# SWM260 register map
File version: 1.0
CPU: CM0 r1p0, little endian, 2 interrupt priority bits
Registers are 32-bit, read-write, no defined reset value unless marked. A register's access mark holds for its fields unless they carry their own. Offsets are from the block's base; [hi:lo] are bit positions; lines under a group give offsets from that group; {n}, {i} and the like mark numbered series; 'fields as' and 'values as' point back to an identical list.

## TIMR0 — Registers group
Base 0x40046800
Same registers: TIMR1 0x40046840, TIMR2 0x40046880, TIMR3 0x400468C0, BTIMR0 0x40048800, BTIMR1 0x40048840, BTIMR2 0x40048880, BTIMR3 0x400488C0
0x00 LOAD
  [24] LOAD
0x04 VALUE ro
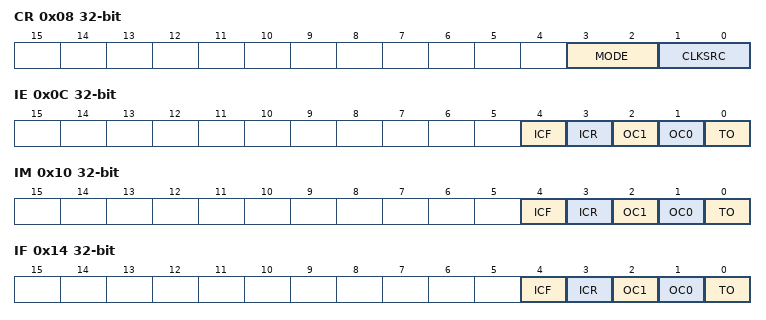
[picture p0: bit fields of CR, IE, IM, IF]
0x08 CR
  [3:2] MODE, [1:0] CLKSRC
0x08 PREDIV (alternate view of CR)
0x0C IE
  [4] ICF, [3] ICR, [2] OC1, [1] OC0, [0] TO
0x10 IM
  [4] ICF, [3] ICR, [2] OC1, [1] OC0, [0] TO
0x14 IF
  [4] ICF, [3] ICR, [2] OC1, [1] OC0, [0] TO
0x18 HALT
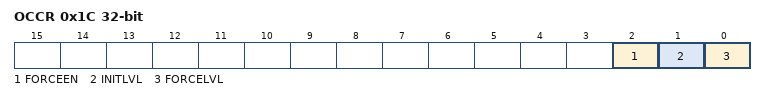
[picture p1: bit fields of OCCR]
0x1C OCCR
  [2] FORCEEN, [1] INITLVL, [0] FORCELVL
0x20 OCMAT0
0x24 OCMAT1
0x28 ICLOW
0x2C ICHIGH

## TIMRG — Registers group
Base 0x40046C00
Same registers: BTIMRG 0x40048C00
0x00 HALLIE
0x04 HALLIM
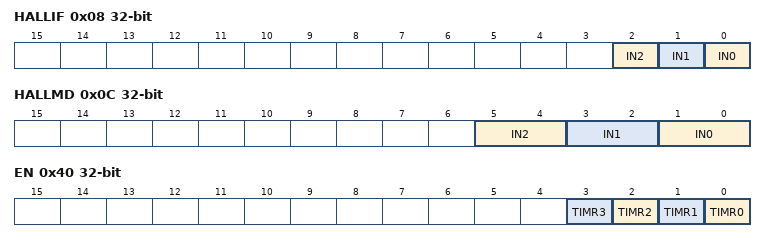
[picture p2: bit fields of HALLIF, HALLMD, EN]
0x08 HALLIF
  [2] IN2, [1] IN1, [0] IN0
0x0C HALLMD
  [5:4] IN2, [3:2] IN1, [1:0] IN0
{0x10+4i} HALLV{i} (i=0..2)
0x40 EN
  [n] TIMR{n} (n=0..3)

## UART0 — Registers group
Base 0x40042000
Same registers: UART1 0x40042800, UART2 0x40043000, UART3 0x40043800, UART4 0x400A3000
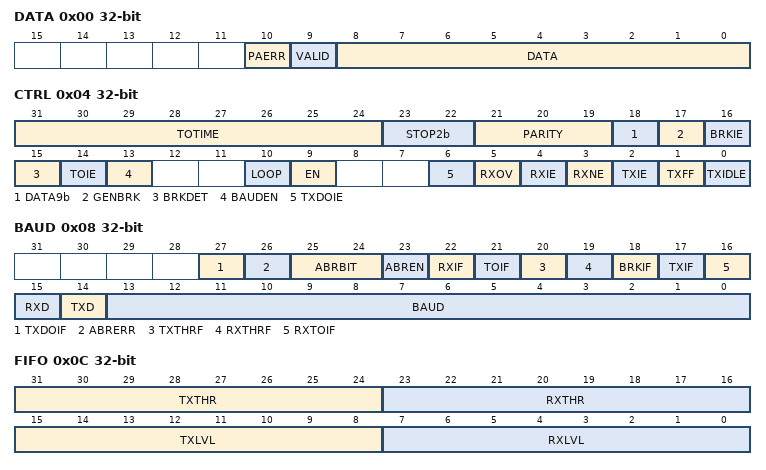
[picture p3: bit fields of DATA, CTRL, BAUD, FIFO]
0x00 DATA
  [10] PAERR, [9] VALID, [8:0] DATA
0x04 CTRL
  [31:24] TOTIME, [23:22] STOP2b, [21:19] PARITY, [18] DATA9b, [17] GENBRK, [16] BRKIE, [15] BRKDET, [14] TOIE, [13] BAUDEN, [10] LOOP, [9] EN, [6] TXDOIE, [5] RXOV, [4] RXIE, [3] RXNE, [2] TXIE, [1] TXFF, [0] TXIDLE
0x08 BAUD
  [27] TXDOIF, [26] ABRERR, [25:24] ABRBIT, [23] ABREN, [22] RXIF, [21] TOIF, [20] TXTHRF, [19] RXTHRF, [18] BRKIF, [17] TXIF, [16] RXTOIF, [15] RXD, [14] TXD, [13:0] BAUD
0x0C FIFO
  [31:24] TXTHR, [23:16] RXTHR, [15:8] TXLVL, [7:0] RXLVL
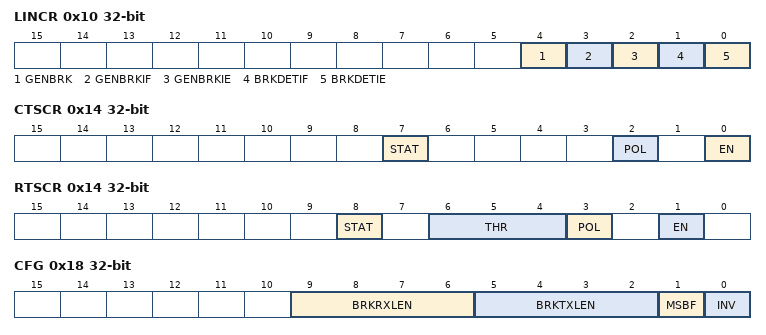
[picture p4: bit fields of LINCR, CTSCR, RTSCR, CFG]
0x10 LINCR
  [4] GENBRK, [3] GENBRKIF, [2] GENBRKIE, [1] BRKDETIF, [0] BRKDETIE
0x14 CTSCR
  [7] STAT, [2] POL, [0] EN
0x14 RTSCR (alternate view of CTSCR)
  [8] STAT, [6:4] THR, [3] POL, [1] EN
0x18 CFG
  [9:6] BRKRXLEN, [5:2] BRKTXLEN, [1] MSBF, [0] INV

## SPI0 — Registers group
Base 0x40044000
Same registers: SPI1 0x40044800
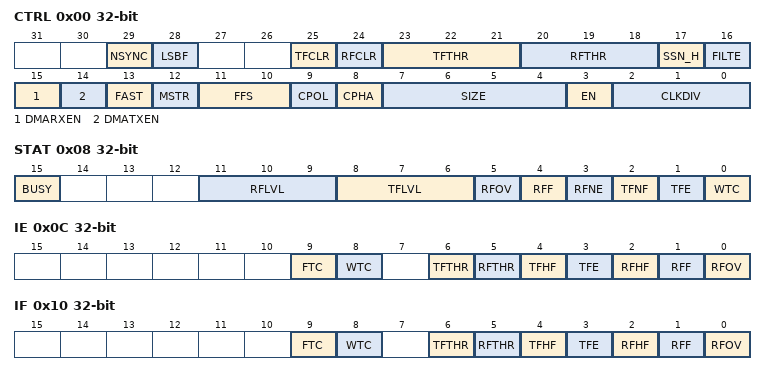
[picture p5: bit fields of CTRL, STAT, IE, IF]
0x00 CTRL
  [29] NSYNC, [28] LSBF, [25] TFCLR, [24] RFCLR, [23:21] TFTHR, [20:18] RFTHR, [17] SSN_H, [16] FILTE, [15] DMARXEN, [14] DMATXEN, [13] FAST, [12] MSTR, [11:10] FFS, [9] CPOL, [8] CPHA, [7:4] SIZE, [3] EN, [2:0] CLKDIV
0x04 DATA
0x08 STAT
  [15] BUSY, [11:9] RFLVL, [8:6] TFLVL, [5] RFOV, [4] RFF, [3] RFNE, [2] TFNF, [1] TFE, [0] WTC
0x0C IE
  [9] FTC, [8] WTC, [6] TFTHR, [5] RFTHR, [4] TFHF, [3] TFE, [2] RFHF, [1] RFF, [0] RFOV
0x10 IF
  fields as IE

## I2C4 — Registers group
Base 0x40045000
0x00 CLKDIV
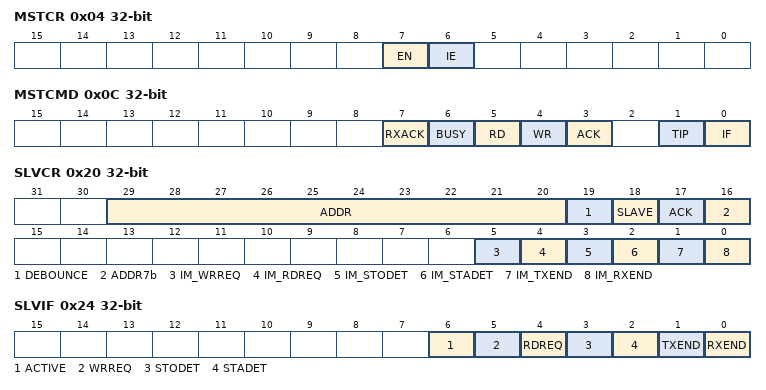
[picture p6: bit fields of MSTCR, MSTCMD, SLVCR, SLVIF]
0x04 MSTCR
  [7] EN, [6] IE
0x08 MSTDAT
0x0C MSTCMD
  [7] RXACK, [6] BUSY, [5] RD, [4] WR, [3] ACK, [1] TIP, [0] IF
0x20 SLVCR
  [29:20] ADDR, [19] DEBOUNCE, [18] SLAVE, [17] ACK, [16] ADDR7b, [5] IM_WRREQ, [4] IM_RDREQ, [3] IM_STODET, [2] IM_STADET, [1] IM_TXEND, [0] IM_RXEND
0x24 SLVIF
  [6] ACTIVE, [5] WRREQ, [4] RDREQ, [3] STODET, [2] STADET, [1] TXEND, [0] RXEND
0x28 SLVTX
0x2C SLVRX
0x30 SLVAM

## ADC0 — Registers group
Base 0x40049000
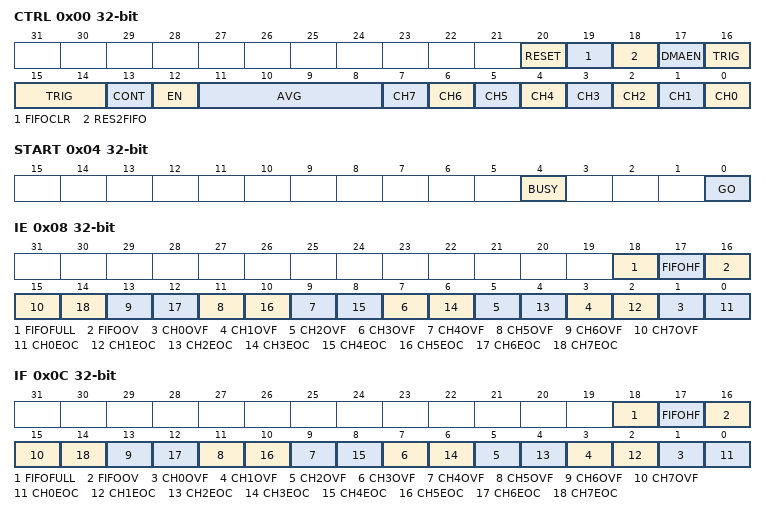
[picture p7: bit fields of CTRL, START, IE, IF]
0x00 CTRL
  [20] RESET, [19] FIFOCLR, [18] RES2FIFO, [17] DMAEN, [16:14] TRIG, [13] CONT, [12] EN, [11:8] AVG, [n] CH{n} (n=0..7)
0x04 START
  [4] BUSY, [0] GO
0x08 IE
  [18] FIFOFULL, [17] FIFOHF, [16] FIFOOV, [2n+1] CH{n}OVF (n=0..7), [2n] CH{n}EOC (n=0..7)
0x0C IF
  fields as IE
{0x10+0x10*i} CH{i} group (i=0..7) — register cluster
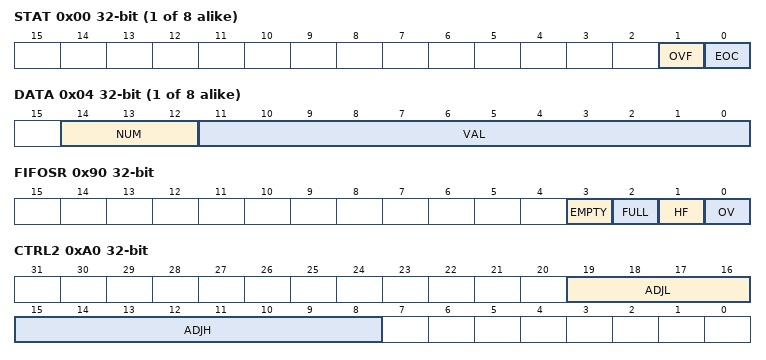
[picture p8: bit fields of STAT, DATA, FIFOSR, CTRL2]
  0x00 STAT
    [1] OVF, [0] EOC
  0x04 DATA
    [14:12] NUM, [11:0] VAL
0x90 FIFOSR
  [3] EMPTY, [2] FULL, [1] HF, [0] OV
0x94 FIFODR
0xA0 CTRL2
  [19:16] ADJL, [15:8] ADJH
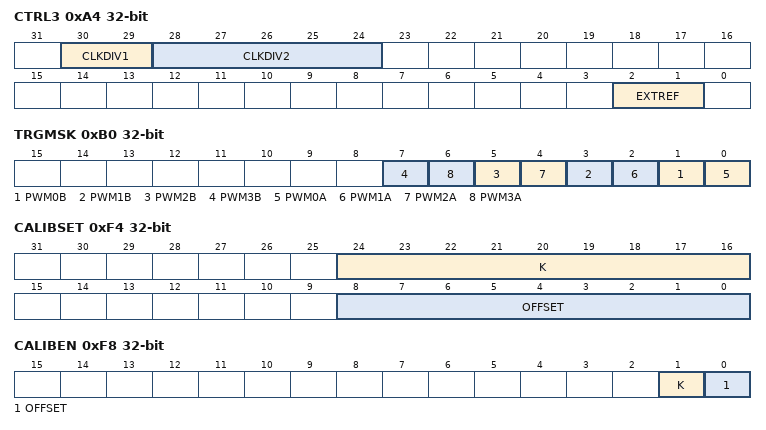
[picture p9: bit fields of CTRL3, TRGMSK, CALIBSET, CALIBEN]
0xA4 CTRL3
  [30:29] CLKDIV1, [28:24] CLKDIV2, [2:1] EXTREF
0xB0 TRGMSK
  [2n+1] PWM{n}B (n=0..3), [2n] PWM{n}A (n=0..3)
0xF4 CALIBSET
  [24:16] K, [8:0] OFFSET
0xF8 CALIBEN
  [1] K, [0] OFFSET

## PWM0 — Registers group
Base 0x40046000
Same registers: PWM1 0x40046040, PWM2 0x40046080, PWM3 0x400460C0
0x00 MODE
0x04 PERA
0x08 HIGHA
0x0C DZA
0x10 PERB
0x14 HIGHB
0x18 DZB
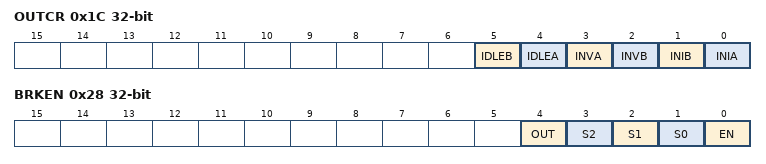
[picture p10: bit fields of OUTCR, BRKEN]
0x1C OUTCR
  [5] IDLEB, [4] IDLEA, [3] INVA, [2] INVB, [1] INIB, [0] INIA
0x20 ADTRGA0
0x24 ADTRGA1
0x28 BRKEN
  [4] OUT, [3] S2, [2] S1, [1] S0, [0] EN
0x2C VALUEA
0x30 VALUEB
0x34 ADTRGB0
0x38 ADTRGB1

## PWMG — Registers group
Base 0x40046200
0x00 CLKDIV
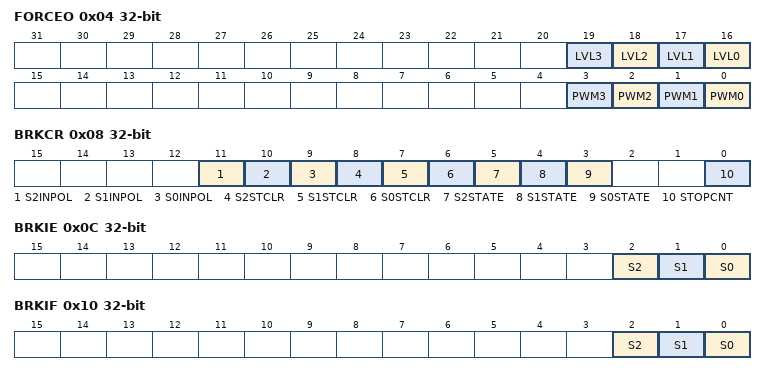
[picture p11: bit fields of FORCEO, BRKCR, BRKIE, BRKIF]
0x04 FORCEO
  [n+16] LVL{n} (n=0..3), [n] PWM{n} (n=0..3)
0x08 BRKCR
  [11] S2INPOL, [10] S1INPOL, [9] S0INPOL, [8] S2STCLR, [7] S1STCLR, [6] S0STCLR, [5] S2STATE, [4] S1STATE, [3] S0STATE, [0] STOPCNT
0x0C BRKIE
  [2] S2, [1] S1, [0] S0
0x10 BRKIF ro
  [2] S2, [1] S1, [0] S0
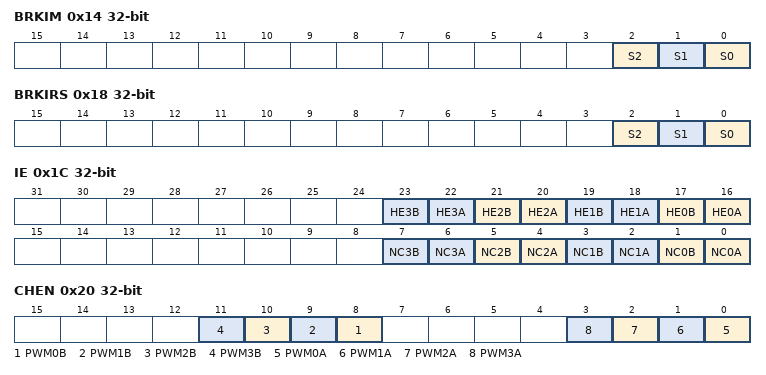
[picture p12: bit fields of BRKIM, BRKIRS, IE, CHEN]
0x14 BRKIM
  [2] S2, [1] S1, [0] S0
0x18 BRKIRS
  [2] S2, [1] S1, [0] S0
0x1C IE
  [2n+17] HE{n}B (n=0..3), [2n+16] HE{n}A (n=0..3), [2n+1] NC{n}B (n=0..3), [2n] NC{n}A (n=0..3)
0x20 CHEN
  [n+8] PWM{n}B (n=0..3), [n] PWM{n}A (n=0..3)
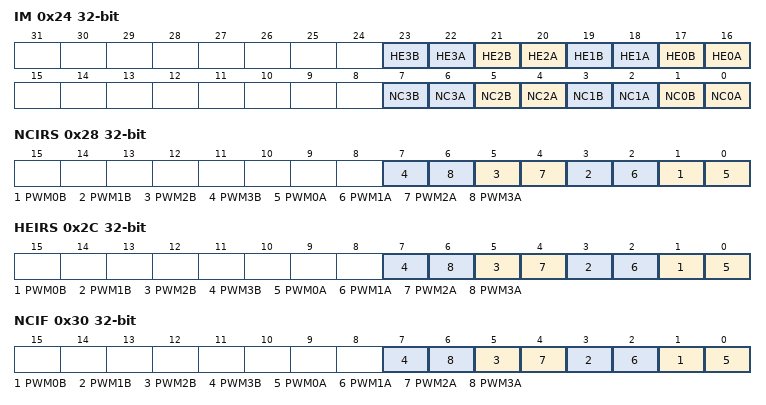
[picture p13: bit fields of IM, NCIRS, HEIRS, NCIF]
0x24 IM
  fields as IE
0x28 NCIRS
  [2n+1] PWM{n}B (n=0..3), [2n] PWM{n}A (n=0..3)
0x2C HEIRS
  [2n+1] PWM{n}B (n=0..3), [2n] PWM{n}A (n=0..3)
0x30 NCIF ro
  [2n+1] PWM{n}B (n=0..3), [2n] PWM{n}A (n=0..3)
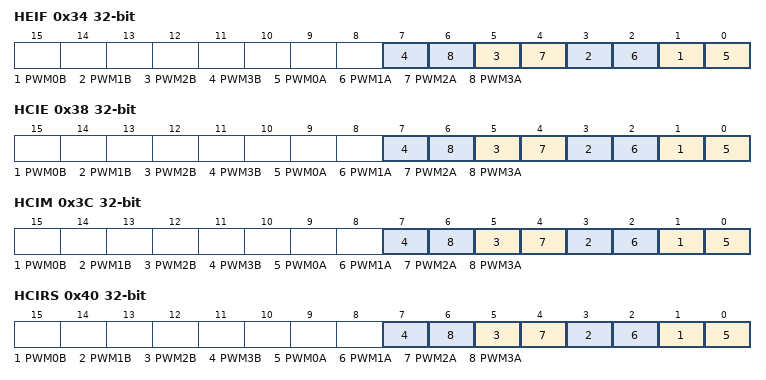
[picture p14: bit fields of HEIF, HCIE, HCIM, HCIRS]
0x34 HEIF ro
  [2n+1] PWM{n}B (n=0..3), [2n] PWM{n}A (n=0..3)
0x38 HCIE
  [2n+1] PWM{n}B (n=0..3), [2n] PWM{n}A (n=0..3)
0x3C HCIM
  [2n+1] PWM{n}B (n=0..3), [2n] PWM{n}A (n=0..3)
0x40 HCIRS
  [2n+1] PWM{n}B (n=0..3), [2n] PWM{n}A (n=0..3)
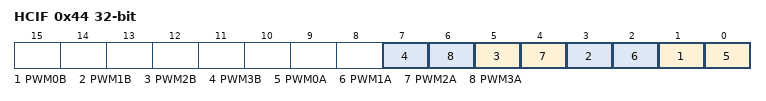
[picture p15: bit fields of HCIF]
0x44 HCIF ro
  [2n+1] PWM{n}B (n=0..3), [2n] PWM{n}A (n=0..3)

## DMA — Registers group
Base 0x40000800
0x00 EN
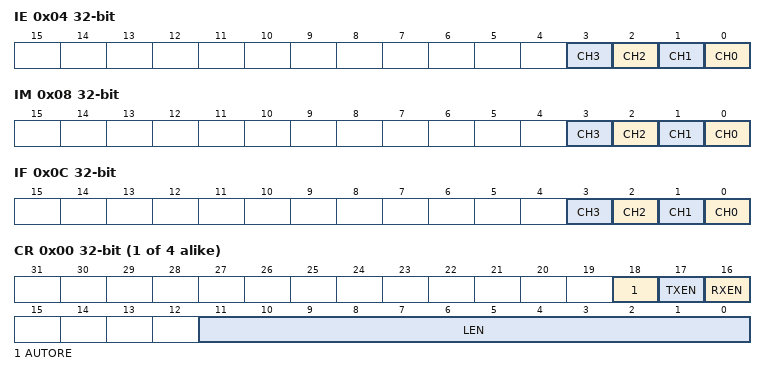
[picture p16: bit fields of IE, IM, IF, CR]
0x04 IE
  [n] CH{n} (n=0..3)
0x08 IM
  [n] CH{n} (n=0..3)
0x0C IF
  [n] CH{n} (n=0..3)
0x10 DSTSGIE
0x14 DSTSGIM
0x18 DSTSGIF
0x1C SRCSGIE
0x20 SRCSGIM
0x24 SRCSGIF
0x3C PRI
{0x40+0x40*i} CH{i} group (i=0..3) — register cluster
  0x00 CR
    [18] AUTORE, [17] TXEN, [16] RXEN, [11:0] LEN
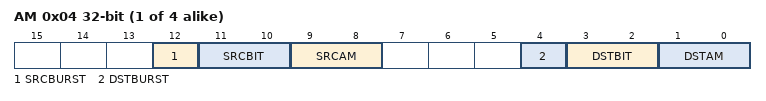
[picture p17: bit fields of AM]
  0x04 AM
    [12] SRCBURST, [11:10] SRCBIT, [9:8] SRCAM, [4] DSTBURST, [3:2] DSTBIT, [1:0] DSTAM
  0x08 DST
  {0x8+4j} DSTSGADDR{j} (j=1..3)
  0x18 MUX
    [10] M1TRGEN, [9:8] M1TRGSRC, [2] M0TRGEN, [1:0] M0TRGSRC
  0x1C SRC
  {0x1C+4j} SRCSGADDR{j} (j=1..3)
  0x2C SR ro
    [29] SRCERR, [28:16] SRCLEN, [13] DSTERR, [12:0] DSTLEN

## FMC — Registers group
Base 0x4004A000
0x00 DATA
0x04 ADDR
  [31] WREN, [30] BUSY, [16:0] ADDR
0x08 ERASE
  [31] REQ, [16] CHIP, [15:10] PAGE
0x0C REMAP
  [6:1] OFFSET, [0] ON
0x10 CFG0
  [17:16] CLK, [10:4] _1US
0x14 CFG1
  [29:27] TNVS, [26:23] TPGS, [22:17] TPROG, [16:14] TNVH, [13:12] TRCV, [11:5] TNVH1, [4:0] TERASE
0x18 CFG2
0x20 STAT
  [4] ERASEDONE, [3] PROGDONE, [2] READBUSY, [1] PROGBUSY, [0] ERASEBUSY

## RTC — Registers group
Base 0x4004B800
0x00 MINSEC
  [11:6] MIN, [5:0] SEC
0x04 DATHUR
  [9:5] DATE, [4:0] HOUR
0x08 MONDAY
  [6:3] MON, [2:0] DAY
0x0C YEAR
0x10 MINSECAL
  [11:6] MIN, [5:0] SEC
0x14 DAYHURAL
  [11] SAT, [10] FRI, [9] THU, [8] WED, [7] TUE, [6] MON, [5] SUN, [4:0] HOUR
0x18 LOAD
  [1] ALARM, [0] TIME
0x1C IE
  [7] QSEC, [6] HSEC, [5] TRIM, [4] ALARM, [3] DATE, [2] HOUR, [1] MIN, [0] SEC
0x20 IF
  fields as IE
0x24 EN
0x28 CFGABLE
0x2C TRIM
  [8] DEC, [7:0] ADJ
0x30 TRIMM
  [3] INC, [2:0] CYCLE
0x60 CALIBCNT
0x64 CALIBEN
0x68 CALIBSR

## WDT — Registers group
Base 0x400A0800
0x00 RSTVAL
0x04 INTVAL
0x08 CR
  [3] LOCK, [2] INTEN, [1] RSTEN, [0] EN
0x0C IF
0x10 FEED
